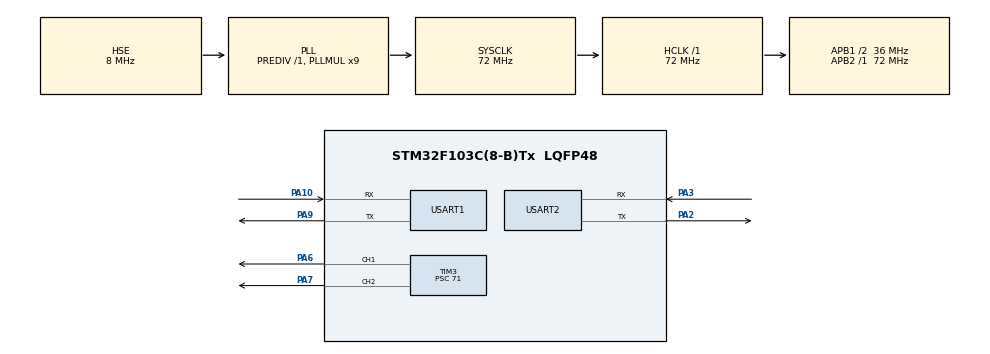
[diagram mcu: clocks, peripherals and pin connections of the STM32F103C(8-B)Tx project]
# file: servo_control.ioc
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Dma.Request0=USART1_TX
Dma.USART1_TX.0.Direction=DMA_MEMORY_TO_PERIPH
Dma.USART1_TX.0.Instance=DMA1_Channel4
Dma.USART1_TX.0.MemDataAlignment=DMA_MDATAALIGN_BYTE
Dma.USART1_TX.0.MemInc=DMA_MINC_ENABLE
Dma.USART1_TX.0.Mode=DMA_NORMAL
Dma.USART1_TX.0.PeriphDataAlignment=DMA_PDATAALIGN_BYTE
Dma.USART1_TX.0.PeriphInc=DMA_PINC_DISABLE
Dma.USART1_TX.0.Priority=DMA_PRIORITY_LOW
FREERTOS.Tasks01=defaultTask,0,128,StartDefaultTask,Default,NULL,Dynamic,NULL,NULL;ServoTask,0,256,StartServoTask,Default,NULL,Dynamic,NULL,NULL
Mcu.Family=STM32F1
Mcu.Name=STM32F103C(8-B)Tx
Mcu.Package=LQFP48
NVIC.DMA1_Channel4_IRQn=true\:5\:0\:false\:false\:true\:true\:false\:true\:true
NVIC.PriorityGroup=NVIC_PRIORITYGROUP_4
NVIC.USART1_IRQn=true\:5\:0\:false\:false\:true\:true\:true\:true\:true
NVIC.USART2_IRQn=true\:5\:0\:false\:false\:true\:true\:true\:true\:true
PA10.Mode=Asynchronous
PA10.Signal=USART1_RX
PA13.Mode=Serial_Wire
PA13.Signal=SYS_JTMS-SWDIO
PA14.Mode=Serial_Wire
PA14.Signal=SYS_JTCK-SWCLK
PA2.Mode=Asynchronous
PA2.Signal=USART2_TX
PA3.Mode=Asynchronous
PA3.Signal=USART2_RX
PA6.Signal=S_TIM3_CH1
PA7.Signal=S_TIM3_CH2
PA9.Mode=Asynchronous
PA9.Signal=USART1_TX
PD0-OSC_IN.Mode=HSE-External-Oscillator
PD0-OSC_IN.Signal=RCC_OSC_IN
PD1-OSC_OUT.Mode=HSE-External-Oscillator
PD1-OSC_OUT.Signal=RCC_OSC_OUT
ProjectManager.HeapSize=0x200
ProjectManager.StackSize=0x400
ProjectManager.TargetToolchain=STM32CubeIDE
RCC.AHBFreq_Value=72000000
RCC.APB1CLKDivider=RCC_HCLK_DIV2
RCC.APB1Freq_Value=36000000
RCC.APB1TimFreq_Value=72000000
RCC.APB2Freq_Value=72000000
RCC.APB2TimFreq_Value=72000000
RCC.HCLKFreq_Value=72000000
RCC.PLLMUL=RCC_PLL_MUL9
RCC.PLLSourceVirtual=RCC_PLLSOURCE_HSE
RCC.SYSCLKFreq_VALUE=72000000
RCC.SYSCLKSource=RCC_SYSCLKSOURCE_PLLCLK
RCC.USBFreq_Value=72000000
SH.S_TIM3_CH1.0=TIM3_CH1,PWM Generation1 CH1
SH.S_TIM3_CH2.0=TIM3_CH2,PWM Generation2 CH2
TIM3.Channel-PWM\ Generation1\ CH1=TIM_CHANNEL_1
TIM3.Channel-PWM\ Generation2\ CH2=TIM_CHANNEL_2
TIM3.Period=19999
TIM3.Prescaler=71
TIM3.Pulse-PWM\ Generation1\ CH1=1500
USART1.VirtualMode=VM_ASYNC
USART2.VirtualMode=VM_ASYNC
VP_FREERTOS_VS_CMSIS_V1.Mode=CMSIS_V1
board=custom

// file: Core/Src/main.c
/* USER CODE BEGIN Header */
/**
  ******************************************************************************
  * @file           : main.c
  * @brief          : Main program body
  ******************************************************************************
  * @attention
  *
  * Copyright (c) 2025 STMicroelectronics.
  * All rights reserved.
  *
  * This software is licensed under terms that can be found in the LICENSE file
  * in the root directory of this software component.
  * If no LICENSE file comes with this software, it is provided AS-IS.
  *
  ******************************************************************************
  */
/* USER CODE END Header */
#include "main.h"
#include "cmsis_os.h"
#include "dma.h"
#include "tim.h"
#include "usart.h"
#include "gpio.h"

void SystemClock_Config(void);
void MX_FREERTOS_Init(void);

int main(void)
{

  /* MCU Configuration--------------------------------------------------------*/

  /* Reset of all peripherals, Initializes the Flash interface and the Systick. */
  HAL_Init();

  /* Configure the system clock */
  SystemClock_Config();

  /* Initialize all configured peripherals */
  MX_GPIO_Init();
  MX_DMA_Init();
  MX_TIM3_Init();
  MX_USART1_UART_Init();
  MX_USART2_UART_Init();
  /* USER CODE BEGIN 2 */

  UART2_InitReceive();    // UART2中断接收初始�?????

  HAL_TIM_PWM_Start(&htim3, TIM_CHANNEL_1);
  HAL_TIM_PWM_Start(&htim3, TIM_CHANNEL_2);

  // init servo and self check
  Servo_Init();
  Servo_SelfTest();

  /* USER CODE END 2 */

  /* Call init function for freertos objects (in freertos.c) */
  MX_FREERTOS_Init();

  /* Start scheduler */
  osKernelStart();
  /* We should never get here as control is now taken by the scheduler */
  /* Infinite loop */
  while (1)
  {

  }
}

void SystemClock_Config(void)
{
  RCC_OscInitTypeDef RCC_OscInitStruct = {0};
  RCC_ClkInitTypeDef RCC_ClkInitStruct = {0};

  /** Initializes the RCC Oscillators according to the specified parameters
  * in the RCC_OscInitTypeDef structure.
  */
  RCC_OscInitStruct.OscillatorType = RCC_OSCILLATORTYPE_HSE;
  RCC_OscInitStruct.HSEState = RCC_HSE_ON;
  RCC_OscInitStruct.HSEPredivValue = RCC_HSE_PREDIV_DIV1;
  RCC_OscInitStruct.HSIState = RCC_HSI_ON;
  RCC_OscInitStruct.PLL.PLLState = RCC_PLL_ON;
  RCC_OscInitStruct.PLL.PLLSource = RCC_PLLSOURCE_HSE;
  RCC_OscInitStruct.PLL.PLLMUL = RCC_PLL_MUL9;
  if (HAL_RCC_OscConfig(&RCC_OscInitStruct) != HAL_OK)
  {
    Error_Handler();
  }

  /** Initializes the CPU, AHB and APB buses clocks
  */
  RCC_ClkInitStruct.ClockType = RCC_CLOCKTYPE_HCLK|RCC_CLOCKTYPE_SYSCLK
                              |RCC_CLOCKTYPE_PCLK1|RCC_CLOCKTYPE_PCLK2;
  RCC_ClkInitStruct.SYSCLKSource = RCC_SYSCLKSOURCE_PLLCLK;
  RCC_ClkInitStruct.AHBCLKDivider = RCC_SYSCLK_DIV1;
  RCC_ClkInitStruct.APB1CLKDivider = RCC_HCLK_DIV2;
  RCC_ClkInitStruct.APB2CLKDivider = RCC_HCLK_DIV1;

  if (HAL_RCC_ClockConfig(&RCC_ClkInitStruct, FLASH_LATENCY_2) != HAL_OK)
  {
    Error_Handler();
  }
}

void Error_Handler(void)
{
  __disable_irq();
  while (1)
  {
  }
}

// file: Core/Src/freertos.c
/* USER CODE BEGIN Header */
/**
  ******************************************************************************
  * File Name          : freertos.c
  * Description        : Code for freertos applications
  ******************************************************************************
  * @attention
  *
  * Copyright (c) 2025 STMicroelectronics.
  * All rights reserved.
  *
  * This software is licensed under terms that can be found in the LICENSE file
  * in the root directory of this software component.
  * If no LICENSE file comes with this software, it is provided AS-IS.
  *
  ******************************************************************************
  */
/* USER CODE END Header */

#include "FreeRTOS.h"
#include "task.h"
#include "main.h"
#include "cmsis_os.h"

/* USER CODE BEGIN Includes */

#include "queue.h"
#include "servo_control.h"
#include "uart2_receive.h"
#include "freertos_queue.h"

/* USER CODE END Includes */

osThreadId defaultTaskHandle;
osThreadId ServoTaskHandle;

void StartDefaultTask(void const * argument);
void StartServoTask(void const * argument);

void MX_FREERTOS_Init(void); /* (MISRA C 2004 rule 8.1) */

/* GetIdleTaskMemory prototype (linked to static allocation support) */
void vApplicationGetIdleTaskMemory( StaticTask_t **ppxIdleTaskTCBBuffer, StackType_t **ppxIdleTaskStackBuffer, uint32_t *pulIdleTaskStackSize );

/* USER CODE BEGIN GET_IDLE_TASK_MEMORY */
static StaticTask_t xIdleTaskTCBBuffer;
static StackType_t xIdleStack[configMINIMAL_STACK_SIZE];

void vApplicationGetIdleTaskMemory( StaticTask_t **ppxIdleTaskTCBBuffer, StackType_t **ppxIdleTaskStackBuffer, uint32_t *pulIdleTaskStackSize )
{
  *ppxIdleTaskTCBBuffer = &xIdleTaskTCBBuffer;
  *ppxIdleTaskStackBuffer = &xIdleStack[0];
  *pulIdleTaskStackSize = configMINIMAL_STACK_SIZE;
  /* place for user code */
}
/* USER CODE END GET_IDLE_TASK_MEMORY */

void MX_FREERTOS_Init(void) {
  /* USER CODE BEGIN Init */

	Queue_Init();

  /* USER CODE END Init */

  /* Create the thread(s) */
  /* definition and creation of defaultTask */
  osThreadDef(defaultTask, StartDefaultTask, osPriorityNormal, 0, 128);
  defaultTaskHandle = osThreadCreate(osThread(defaultTask), NULL);

  /* definition and creation of ServoTask */
  osThreadDef(ServoTask, StartServoTask, osPriorityNormal, 0, 256);
  ServoTaskHandle = osThreadCreate(osThread(ServoTask), NULL);

}

void StartDefaultTask(void const * argument)
{
  for(;;)
  {
    osDelay(1);
  }
}

void StartServoTask(void const * argument)
{
  /* USER CODE BEGIN StartServoTask */
  Offset_t offset;

  /* Infinite loop */
  for(;;)
  {
	// 阻塞等待队列数据
	if (xQueueReceive(offsetQueue, &offset, portMAX_DELAY) == pdPASS)
	{
	  // 调用舵机控制函数
	  ControlServoWithDX(offset.dx);
	}

    osDelay(1);
  }
  /* USER CODE END StartServoTask */
}
